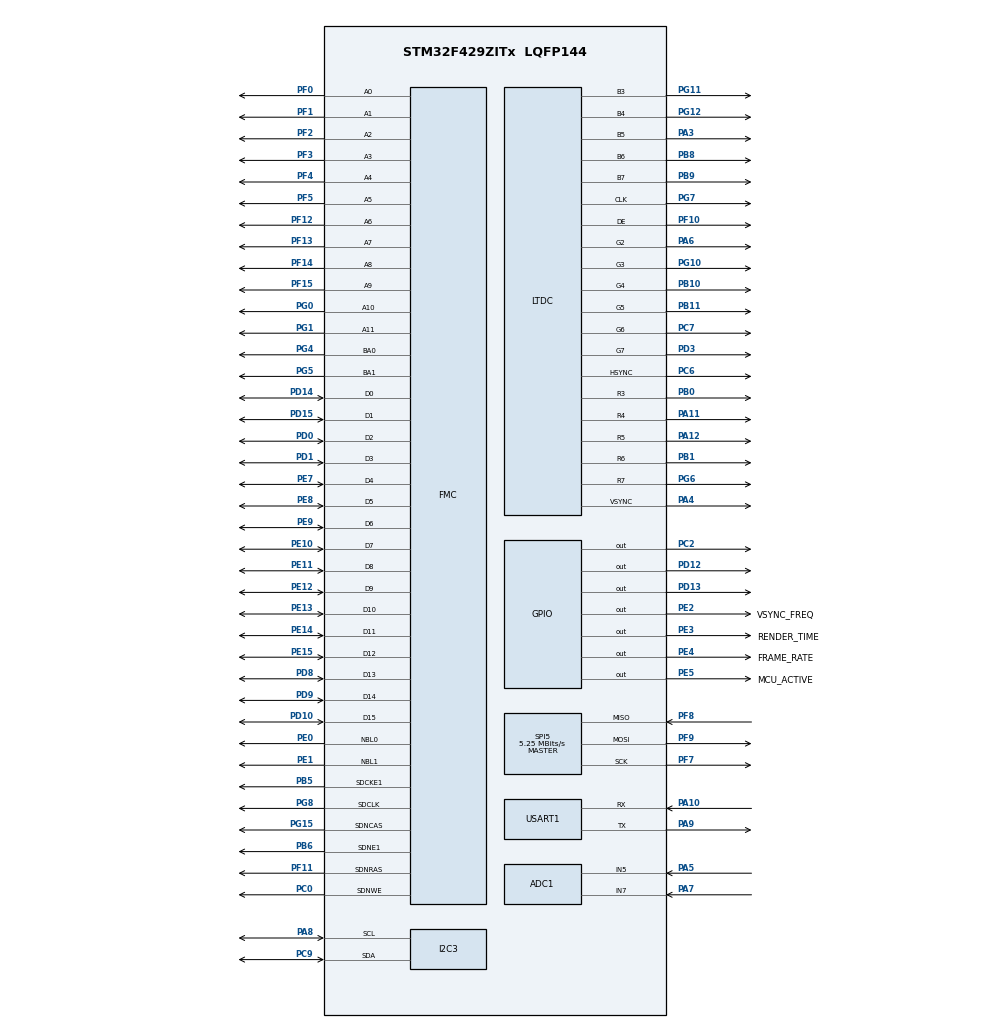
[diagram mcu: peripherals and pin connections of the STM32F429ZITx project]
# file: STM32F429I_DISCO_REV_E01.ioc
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ADC1.Channel-0\#ChannelRegularConversion=ADC_CHANNEL_5
ADC1.Channel-1\#ChannelRegularConversion=ADC_CHANNEL_7
ADC1.NbrOfConversion=2
ADC1.NbrOfConversionFlag=1
ADC1.Rank-0\#ChannelRegularConversion=1
ADC1.Rank-1\#ChannelRegularConversion=2
ADC1.SamplingTime-0\#ChannelRegularConversion=ADC_SAMPLETIME_3CYCLES
ADC1.SamplingTime-1\#ChannelRegularConversion=ADC_SAMPLETIME_3CYCLES
ADC1.master=1
DMA2D.ColorMode=DMA2D_OUTPUT_RGB565
FMC.CASLatency1=FMC_SDRAM_CAS_LATENCY_3
FMC.ExitSelfRefreshDelay1=7
FMC.LoadToActiveDelay1=2
FMC.RCDDelay1=2
FMC.RPDelay1=2
FMC.ReadPipeDelay1=FMC_SDRAM_RPIPE_DELAY_1
FMC.RowCycleDelay1=7
FMC.SDClockPeriod1=FMC_SDRAM_CLOCK_PERIOD_2
FMC.SelfRefreshTime1=4
FMC.WriteRecoveryTime1=3
FREERTOS.Tasks01=defaultTask,24,128,StartDefaultTask,Default,NULL,Dynamic,NULL,NULL;GUI_Task,24,8192,TouchGFX_Task,As external,NULL,Dynamic,NULL,NULL
FREERTOS.configMAX_PRIORITIES=56
FREERTOS.configTOTAL_HEAP_SIZE=65536
FREERTOS.configUSE_APPLICATION_TASK_TAG=1
FREERTOS.configUSE_NEWLIB_REENTRANT=1
I2C3.Analog_Filter=I2C_ANALOGFILTER_DISABLE
LTDC.ActiveH=320
LTDC.ActiveW=240
LTDC.Alpha_L0=255
LTDC.BlendingFactor1_L0=LTDC_BLENDING_FACTOR1_CA
LTDC.BlendingFactor2_L0=LTDC_BLENDING_FACTOR2_CA
LTDC.Blue_L0=0
LTDC.HBP=20
LTDC.HFP=10
LTDC.HSync=10
LTDC.ImageHeight_L0=320
LTDC.ImageWidth_L0=240
LTDC.Layers=0
LTDC.PixelFormat_L0=LTDC_PIXEL_FORMAT_RGB565
LTDC.VFP=4
LTDC.VSync=2
LTDC.WindowX1_L0=240
LTDC.WindowY1_L0=320
Mcu.Family=STM32F4
Mcu.Name=STM32F429ZITx
Mcu.Package=LQFP144
NVIC.ADC_IRQn=true\:5\:0\:false\:false\:true\:true\:true\:true\:true
NVIC.DMA2D_IRQn=true\:5\:0\:true\:false\:true\:false\:true\:true\:true
NVIC.LTDC_IRQn=true\:5\:0\:true\:false\:true\:false\:true\:true\:true
NVIC.PriorityGroup=NVIC_PRIORITYGROUP_4
NVIC.TIM6_DAC_IRQn=true\:0\:0\:false\:false\:true\:false\:false\:true\:true
NVIC.TimeBase=TIM6_DAC_IRQn
NVIC.TimeBaseIP=TIM6
NVIC.USART1_IRQn=true\:5\:0\:false\:false\:true\:true\:true\:true\:true
PA10.Mode=Asynchronous
PA10.Signal=USART1_RX
PA11.GPIO_Speed=GPIO_SPEED_FREQ_HIGH
PA11.Mode=RGB565
PA11.Signal=LTDC_R4
PA12.GPIO_Speed=GPIO_SPEED_FREQ_HIGH
PA12.Mode=RGB565
PA12.Signal=LTDC_R5
PA3.GPIO_Speed=GPIO_SPEED_FREQ_HIGH
PA3.Mode=RGB565
PA3.Signal=LTDC_B5
PA4.GPIO_Speed=GPIO_SPEED_FREQ_HIGH
PA4.Mode=RGB565
PA4.Signal=LTDC_VSYNC
PA5.Signal=ADCx_IN5
PA6.GPIO_Speed=GPIO_SPEED_FREQ_HIGH
PA6.Mode=RGB565
PA6.Signal=LTDC_G2
PA7.Signal=ADCx_IN7
PA8.GPIO_Pu=GPIO_PULLUP
PA8.Mode=I2C
PA8.Signal=I2C3_SCL
PA9.Mode=Asynchronous
PA9.Signal=USART1_TX
PB0.GPIO_Speed=GPIO_SPEED_FREQ_HIGH
PB0.Mode=RGB565
PB0.Signal=LTDC_R3
PB1.GPIO_Speed=GPIO_SPEED_FREQ_HIGH
PB1.Mode=RGB565
PB1.Signal=LTDC_R6
PB10.GPIO_Speed=GPIO_SPEED_FREQ_HIGH
PB10.Mode=RGB565
PB10.Signal=LTDC_G4
PB11.GPIO_Speed=GPIO_SPEED_FREQ_HIGH
PB11.Mode=RGB565
PB11.Signal=LTDC_G5
PB5.Mode=SdramChipSelect2_1
PB5.Signal=FMC_SDCKE1
PB6.Mode=SdramChipSelect2_1
PB6.Signal=FMC_SDNE1
PB8.GPIO_Speed=GPIO_SPEED_FREQ_HIGH
PB8.Mode=RGB565
PB8.Signal=LTDC_B6
PB9.GPIO_Speed=GPIO_SPEED_FREQ_HIGH
PB9.Mode=RGB565
PB9.Signal=LTDC_B7
PC0.Signal=FMC_SDNWE
PC2.GPIO_Speed=GPIO_SPEED_FREQ_HIGH
PC2.Signal=GPIO_Output
PC6.GPIO_Speed=GPIO_SPEED_FREQ_HIGH
PC6.Mode=RGB565
PC6.Signal=LTDC_HSYNC
PC7.GPIO_Speed=GPIO_SPEED_FREQ_HIGH
PC7.Mode=RGB565
PC7.Signal=LTDC_G6
PC9.GPIO_Pu=GPIO_PULLUP
PC9.Mode=I2C
PC9.Signal=I2C3_SDA
PD0.Signal=FMC_D2_DA2
PD1.Signal=FMC_D3_DA3
PD10.Signal=FMC_D15_DA15
PD12.GPIO_Speed=GPIO_SPEED_FREQ_HIGH
PD12.Signal=GPIO_Output
PD13.GPIO_Speed=GPIO_SPEED_FREQ_HIGH
PD13.Signal=GPIO_Output
PD14.Signal=FMC_D0_DA0
PD15.Signal=FMC_D1_DA1
PD3.GPIO_Speed=GPIO_SPEED_FREQ_HIGH
PD3.Mode=RGB565
PD3.Signal=LTDC_G7
PD8.Signal=FMC_D13_DA13
PD9.Signal=FMC_D14_DA14
PE0.Signal=FMC_NBL0
PE1.Signal=FMC_NBL1
PE10.Signal=FMC_D7_DA7
PE11.Signal=FMC_D8_DA8
PE12.Signal=FMC_D9_DA9
PE13.Signal=FMC_D10_DA10
PE14.Signal=FMC_D11_DA11
PE15.Signal=FMC_D12_DA12
PE2.GPIO_Label=VSYNC_FREQ
PE2.GPIO_Speed=GPIO_SPEED_FREQ_VERY_HIGH
PE2.Signal=GPIO_Output
PE3.GPIO_Label=RENDER_TIME
PE3.GPIO_Speed=GPIO_SPEED_FREQ_VERY_HIGH
PE3.Signal=GPIO_Output
PE4.GPIO_Label=FRAME_RATE
PE4.GPIO_Speed=GPIO_SPEED_FREQ_VERY_HIGH
PE4.Signal=GPIO_Output
PE5.GPIO_Label=MCU_ACTIVE
PE5.GPIO_Speed=GPIO_SPEED_FREQ_VERY_HIGH
PE5.Signal=GPIO_Output
PE7.Signal=FMC_D4_DA4
PE8.Signal=FMC_D5_DA5
PE9.Signal=FMC_D6_DA6
PF0.Signal=FMC_A0
PF1.Signal=FMC_A1
PF10.GPIO_Speed=GPIO_SPEED_FREQ_HIGH
PF10.Mode=RGB565
PF10.Signal=LTDC_DE
PF11.Signal=FMC_SDNRAS
PF12.Signal=FMC_A6
PF13.Signal=FMC_A7
PF14.Signal=FMC_A8
PF15.Signal=FMC_A9
PF2.Signal=FMC_A2
PF3.Signal=FMC_A3
PF4.Signal=FMC_A4
PF5.Signal=FMC_A5
PF7.Mode=Full_Duplex_Master
PF7.Signal=SPI5_SCK
PF8.Mode=Full_Duplex_Master
PF8.Signal=SPI5_MISO
PF9.Mode=Full_Duplex_Master
PF9.Signal=SPI5_MOSI
PG0.Signal=FMC_A10
PG1.Signal=FMC_A11
PG10.GPIO_Speed=GPIO_SPEED_FREQ_HIGH
PG10.Mode=RGB565
PG10.Signal=LTDC_G3
PG11.GPIO_Speed=GPIO_SPEED_FREQ_HIGH
PG11.Mode=RGB565
PG11.Signal=LTDC_B3
PG12.GPIO_Speed=GPIO_SPEED_FREQ_HIGH
PG12.Mode=RGB565
PG12.Signal=LTDC_B4
PG15.Signal=FMC_SDNCAS
PG4.Signal=FMC_A14_BA0
PG5.Signal=FMC_A15_BA1
PG6.GPIO_Speed=GPIO_SPEED_FREQ_HIGH
PG6.Mode=RGB565
PG6.Signal=LTDC_R7
PG7.GPIO_Speed=GPIO_SPEED_FREQ_HIGH
PG7.Mode=RGB565
PG7.Signal=LTDC_CLK
PG8.Signal=FMC_SDCLK
PH0/OSC_IN.Mode=HSE-External-Oscillator
PH0/OSC_IN.Signal=RCC_OSC_IN
PH1/OSC_OUT.Mode=HSE-External-Oscillator
PH1/OSC_OUT.Signal=RCC_OSC_OUT
ProjectManager.HeapSize=0xA00
ProjectManager.StackSize=0xA00
ProjectManager.TargetToolchain=STM32CubeIDE
RCC.48MHZClocksFreq_Value=84000000
RCC.AHBFreq_Value=168000000
RCC.APB1CLKDivider=RCC_HCLK_DIV4
RCC.APB1Freq_Value=42000000
RCC.APB1TimFreq_Value=84000000
RCC.APB2CLKDivider=RCC_HCLK_DIV2
RCC.APB2Freq_Value=84000000
RCC.APB2TimFreq_Value=168000000
RCC.CortexFreq_Value=168000000
RCC.HCLKFreq_Value=168000000
RCC.HSE_VALUE=8000000
RCC.HSI_VALUE=16000000
RCC.LSE_VALUE=32768
RCC.PLLM=8
RCC.PLLN=336
RCC.PLLSAIDivR=RCC_PLLSAIDIVR_8
RCC.PLLSAIN=192
RCC.PLLSAIR=4
RCC.PLLSourceVirtual=RCC_PLLSOURCE_HSE
RCC.SYSCLKFreq_VALUE=168000000
RCC.SYSCLKSource=RCC_SYSCLKSOURCE_PLLCLK
RCC.VCOOutputFreq_Value=336000000
SH.ADCx_IN5.0=ADC1_IN5,IN5
SH.ADCx_IN7.0=ADC1_IN7,IN7
SH.FMC_A0.0=FMC_A0,12b-sda1
SH.FMC_A1.0=FMC_A1,12b-sda1
SH.FMC_A10.0=FMC_A10,12b-sda1
SH.FMC_A11.0=FMC_A11,12b-sda1
SH.FMC_A14_BA0.0=FMC_BA0,FourSdramBanks1
SH.FMC_A15_BA1.0=FMC_BA1,FourSdramBanks1
SH.FMC_A2.0=FMC_A2,12b-sda1
SH.FMC_A3.0=FMC_A3,12b-sda1
SH.FMC_A4.0=FMC_A4,12b-sda1
SH.FMC_A5.0=FMC_A5,12b-sda1
SH.FMC_A6.0=FMC_A6,12b-sda1
SH.FMC_A7.0=FMC_A7,12b-sda1
SH.FMC_A8.0=FMC_A8,12b-sda1
SH.FMC_A9.0=FMC_A9,12b-sda1
SH.FMC_D0_DA0.0=FMC_D0,sd-16b-d1
SH.FMC_D10_DA10.0=FMC_D10,sd-16b-d1
SH.FMC_D11_DA11.0=FMC_D11,sd-16b-d1
SH.FMC_D12_DA12.0=FMC_D12,sd-16b-d1
SH.FMC_D13_DA13.0=FMC_D13,sd-16b-d1
SH.FMC_D14_DA14.0=FMC_D14,sd-16b-d1
SH.FMC_D15_DA15.0=FMC_D15,sd-16b-d1
SH.FMC_D1_DA1.0=FMC_D1,sd-16b-d1
SH.FMC_D2_DA2.0=FMC_D2,sd-16b-d1
SH.FMC_D3_DA3.0=FMC_D3,sd-16b-d1
SH.FMC_D4_DA4.0=FMC_D4,sd-16b-d1
SH.FMC_D5_DA5.0=FMC_D5,sd-16b-d1
SH.FMC_D6_DA6.0=FMC_D6,sd-16b-d1
SH.FMC_D7_DA7.0=FMC_D7,sd-16b-d1
SH.FMC_D8_DA8.0=FMC_D8,sd-16b-d1
SH.FMC_D9_DA9.0=FMC_D9,sd-16b-d1
SH.FMC_NBL0.0=FMC_NBL0,Sd2ByteEnable1
SH.FMC_NBL1.0=FMC_NBL1,Sd2ByteEnable1
SH.FMC_SDCLK.0=FMC_SDCLK,12b-sda1
SH.FMC_SDNCAS.0=FMC_SDNCAS,12b-sda1
SH.FMC_SDNRAS.0=FMC_SDNRAS,12b-sda1
SH.FMC_SDNWE.0=FMC_SDNWE,12b-sda1
SPI5.BaudRatePrescaler=SPI_BAUDRATEPRESCALER_16
SPI5.CLKPolarity=SPI_POLARITY_LOW
SPI5.CRCCalculation=SPI_CRCCALCULATION_DISABLE
SPI5.CalculateBaudRate=5.25 MBits/s
SPI5.Direction=SPI_DIRECTION_2LINES
SPI5.Mode=SPI_MODE_MASTER
SPI5.VirtualType=VM_MASTER
STMicroelectronics.X-CUBE-TOUCHGFX.4.23.2.ApplicationCcGraphicsJjApplication=TouchGFXOoGenerator
STMicroelectronics.X-CUBE-TOUCHGFX.4.23.2.tgfx_buffering_strategy=Double
STMicroelectronics.X-CUBE-TOUCHGFX.4.23.2.tgfx_display_interface=disp_ltdc
STMicroelectronics.X-CUBE-TOUCHGFX.4.23.2.tgfx_hardware_accelerator=dma_2d
STMicroelectronics.X-CUBE-TOUCHGFX.4.23.2.tgfx_vector_fonts=Enabled
STMicroelectronics.X-CUBE-TOUCHGFX.4.23.2.tgfx_vector_rendering=Software
STMicroelectronics.X-CUBE-TOUCHGFX.4.23.2.tgfx_vsync=vsync_ltdc
USART1.VirtualMode=VM_ASYNC
VP_CRC_VS_CRC.Mode=CRC_Activate
VP_DMA2D_VS_DMA2D.Mode=DMA2D_Activate
VP_FREERTOS_VS_CMSIS_V2.Mode=CMSIS_V2
VP_STMicroelectronics.X-CUBE-TOUCHGFX_VS_GraphicsJjApplication_4.23.2.Mode=GraphicsJjApplication
VP_SYS_VS_tim6.Mode=TIM6
board=custom

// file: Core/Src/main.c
/* USER CODE BEGIN Header */
/**
 ******************************************************************************
 * @file           : main.c
 * @brief          : Main program body
 ******************************************************************************
 * @attention
 *
 * <h2><center>&copy; Copyright (c) 2020 STMicroelectronics.
 * All rights reserved.</center></h2>
 *
 * This software component is licensed by ST under Ultimate Liberty license
 * SLA0044, the "License"; You may not use this file except in compliance with
 * the License. You may obtain a copy of the License at:
 *                             www.st.com/SLA0044
 *
 ******************************************************************************
 */
//#define DISPLAY_MENU_COMMAND 0
/* USER CODE END Header */
#include "main.h"
#include "gpio.h"
#include "crc.h"
#include "i2c.h"
#include "spi.h"
#include "ltdc.h"
#include "dma.h"
#include "adc.h"
#include "uart.h"
#include "fmc.h"
#include "clock.h"
#include "cmsis_os.h"
#include "app_touchgfx.h"
#include "semphr.h"

/* USER CODE BEGIN Includes */
#include "Components/ili9341/ili9341.h"
#include "temp_sens.h"
#include "data_UI_def.h"
#include "date_time_def.h"
#include "cli.h"
#include "utilities.h"

/* USER CODE END Includes */

/* USER CODE BEGIN PV */
TaskHandle_t GUI_TaskHandle;
TaskHandle_t GetSensData_TaskHandle;
TaskHandle_t CLI_TaskHandle;

BaseType_t GUI_TaskFlag;
BaseType_t GetSensData_TaskFlag;
BaseType_t CLI_TaskFlag;

xQueueHandle dataQueue;
xQueueHandle cliQueue;

xSemaphoreHandle i2c_semaphore;

/* USER CODE END PV */

void CLI_Task(void *argument);
void GetSensDataTask(void *argument);
extern void TouchGFX_Task(void *argument);
void setBrightness(uint8_t);

/* Link function for LCD peripheral */
void LCD_IO_Init(void);
void LCD_IO_WriteData(uint16_t RegValue);
void LCD_IO_WriteReg(uint8_t Reg);
uint32_t LCD_IO_ReadData(uint16_t RegValue, uint8_t ReadSize);
void LCD_Delay(uint32_t delay);

/* IOExpander IO functions */
void IOE_Init(void);
void IOE_ITConfig(void);
void IOE_Delay(uint32_t Delay);
void IOE_Write(uint8_t Addr, uint8_t Reg, uint8_t Value);
uint8_t IOE_Read(uint8_t Addr, uint8_t Reg);
uint16_t IOE_ReadMultiple(uint8_t Addr, uint8_t Reg, uint8_t *pBuffer,
		uint16_t Length);

/* USER CODE END PFP */

int main(void) {

	/* USER CODE BEGIN 1 */
	i2c_semaphore = xSemaphoreCreateBinary();
	xSemaphoreGive(i2c_semaphore); //After creation to be free

	/* USER CODE END 1 */

	/* MCU Configuration--------------------------------------------------------*/

	/* Reset of all peripherals, Initializes the Flash interface and the Systick. */
	HAL_Init();

	/* Configure the system clock */
	SystemClock_Config();

	/* Initialize all configured peripherals */
	MX_GPIO_Init();
	MX_CRC_Init();
	MX_I2C3_Init();
	MX_SPI5_Init();
	MX_FMC_Init();
	MX_LTDC_Init();
	MX_DMA2D_Init();
	MX_ADC1_Init();
	MX_USART1_UART_Init();
	MX_TouchGFX_Init();
	/* Call PreOsInit function */
	MX_TouchGFX_PreOSInit();
	/* USER CODE BEGIN 2 */

	/* Init BME680*/

	/*Task creation*/
	GUI_TaskFlag = xTaskCreate(TouchGFX_Task, "TouchGFX_Task", 8192, NULL, osPriorityNormal,
			&GUI_TaskHandle);

	GetSensData_TaskFlag = xTaskCreate(GetSensDataTask, "GetSensDataTask", 128, NULL, osPriorityNormal,
			&GetSensData_TaskHandle);

	CLI_TaskFlag = xTaskCreate(CLI_Task, "Command Line Interface", 128, NULL, osPriorityNormal,
			&CLI_TaskHandle);

	dataQueue = xQueueCreate(1, sizeof(SensData_t));
	cliQueue = xQueueCreate(1, sizeof(SensData_t));

	/*Check if task and semaphore creation is successful*/
	if(GUI_TaskFlag != pdPASS){
		vTaskDelete(GUI_TaskHandle);
	}
	if(GetSensData_TaskFlag != pdPASS){
		vTaskDelete(GetSensData_TaskHandle);
	}
	if(CLI_TaskFlag != pdPASS){
		vTaskDelete(CLI_TaskHandle);
	}
	if(i2c_semaphore == NULL){

		/* Indicates semaphore creation failed*/
		HAL_GPIO_WritePin(GPIOG, GPIO_PIN_14, GPIO_PIN_SET);
	}
	if(dataQueue == NULL){
		HAL_GPIO_WritePin(GPIOG, GPIO_PIN_14, GPIO_PIN_SET);
	}
	if(cliQueue == NULL){
			HAL_GPIO_WritePin(GPIOG, GPIO_PIN_14, GPIO_PIN_SET);
	}

	vQueueAddToRegistry(dataQueue, "DataQueue");
	vQueueAddToRegistry(dataQueue, "CLIQueue");

	/*Start freeRTOS scheduler*/
	vTaskStartScheduler();
	/* USER CODE END 2 */

	while (1) {

	}
}

/**
 * @brief  IOE Low Level Initialization.
 */
void IOE_Init(void) {
	//Dummy function called when initializing to stmpe811 to setup the i2c.
	//This is done with cubmx and is therfore not done here.
}

/**
 * @brief  IOE Low Level Interrupt configuration.
 */
void IOE_ITConfig(void) {
	//Dummy function called when initializing to stmpe811 to setup interupt for the i2c.
	//The interupt is not used in our case, therefore nothing is done here.
}

/**
 * @brief  IOE Writes single data operation.
 * @param  Addr: I2C Address
 * @param  Reg: Reg Address
 * @param  Value: Data to be written
 */
void IOE_Write(uint8_t Addr, uint8_t Reg, uint8_t Value) {
	I2C3_WriteData(Addr, Reg, Value);
}

/**
 * @brief  IOE Reads single data.
 * @param  Addr: I2C Address
 * @param  Reg: Reg Address
 * @retval The read data
 */
uint8_t IOE_Read(uint8_t Addr, uint8_t Reg) {
	return I2C3_ReadData(Addr, Reg);
}

/**
 * @brief  IOE Reads multiple data.
 * @param  Addr: I2C Address
 * @param  Reg: Reg Address
 * @param  pBuffer: pointer to data buffer
 * @param  Length: length of the data
 * @retval 0 if no problems to read multiple data
 */
uint16_t IOE_ReadMultiple(uint8_t Addr, uint8_t Reg, uint8_t *pBuffer,
		uint16_t Length) {
	return I2C3_ReadBuffer(Addr, Reg, pBuffer, Length);
}

/**
 * @brief  IOE Delay.
 * @param  Delay in ms
 */
void IOE_Delay(uint32_t Delay) {
	HAL_Delay(Delay);
}

void LCD_IO_Init(void) {
	/* Set or Reset the control line */
	HAL_GPIO_WritePin(GPIOC, GPIO_PIN_2, GPIO_PIN_RESET);
	HAL_GPIO_WritePin(GPIOC, GPIO_PIN_2, GPIO_PIN_SET);
}

/**
 * @brief  Writes register value.
 */
void LCD_IO_WriteData(uint16_t RegValue) {
	/* Set WRX to send data */
	HAL_GPIO_WritePin(GPIOD, GPIO_PIN_13, GPIO_PIN_SET);

	/* Reset LCD control line(/CS) and Send data */
	HAL_GPIO_WritePin(GPIOC, GPIO_PIN_2, GPIO_PIN_RESET);
	SPI5_Write(RegValue);

	/* Deselect: Chip Select high */
	HAL_GPIO_WritePin(GPIOC, GPIO_PIN_2, GPIO_PIN_SET);
}

/**
 * @brief  Writes register address.
 */
void LCD_IO_WriteReg(uint8_t Reg) {
	/* Reset WRX to send command */
	HAL_GPIO_WritePin(GPIOD, GPIO_PIN_13, GPIO_PIN_RESET);

	/* Reset LCD control line(/CS) and Send command */
	HAL_GPIO_WritePin(GPIOC, GPIO_PIN_2, GPIO_PIN_RESET);
	SPI5_Write(Reg);

	/* Deselect: Chip Select high */
	HAL_GPIO_WritePin(GPIOC, GPIO_PIN_2, GPIO_PIN_SET);
}

/**
 * @brief  Reads register value.
 * @param  RegValue Address of the register to read
 * @param  ReadSize Number of bytes to read
 * @retval Content of the register value
 */
uint32_t LCD_IO_ReadData(uint16_t RegValue, uint8_t ReadSize) {
	uint32_t readvalue = 0;

	/* Select: Chip Select low */
	HAL_GPIO_WritePin(GPIOC, GPIO_PIN_2, GPIO_PIN_RESET);

	/* Reset WRX to send command */
	HAL_GPIO_WritePin(GPIOD, GPIO_PIN_13, GPIO_PIN_RESET);

	SPI5_Write(RegValue);

	readvalue = SPI5_Read(ReadSize);

	/* Set WRX to send data */
	HAL_GPIO_WritePin(GPIOD, GPIO_PIN_13, GPIO_PIN_SET);

	/* Deselect: Chip Select high */
	HAL_GPIO_WritePin(GPIOC, GPIO_PIN_2, GPIO_PIN_SET);

	return readvalue;
}

/**
 * @brief  Wait for loop in ms.
 * @param  Delay in ms.
 */
void LCD_Delay(uint32_t Delay) {
	HAL_Delay(Delay);
}

void GetSensDataTask(void *argument) {

	SensData_t data_UI;
	SensorInit(&sensor_In, &meas_period_In, SENS_IN_NUM);
	SensorInit(&sensor_Out, &meas_period_Out, SENS_OUT_NUM);

	for (;;) {

		ADC_Select_CH5(&data_UI); //get ADC value from PA5 <Ambient light>

		ADC_Select_CH7(&data_UI); //get ADC value from PA7 <Gas sensor>

		GetBMEdata(&data_UI);

		if(uxQueueSpacesAvailable(dataQueue) == 1){

			xQueueSend(dataQueue, &data_UI,0);
		}

		if(uxQueueSpacesAvailable(cliQueue) == 1){

			xQueueSend(cliQueue, &data_UI,0);
		}

		osDelay(500);
	}
}

void CLI_Task(void *argument) {

	SensData_t data_UI;

	HAL_UART_Receive_IT(&huart1, (uint8_t*) &msg[msgIDX], 1);
	for (;;) {

		if(uxQueueSpacesAvailable(cliQueue) == 0){

			xQueueReceive(cliQueue, &data_UI, 0);
		}

		xTaskNotifyWait(0, 1, NULL, portMAX_DELAY);

		CLIHandler(&data_UI, &huart1, msg, &msgIDX);

	}
}

void HAL_UART_RxCpltCallback(UART_HandleTypeDef *huart) {
	xTaskNotifyFromISR(CLI_TaskHandle, 0, eNoAction, NULL);
	HAL_UART_Transmit(&huart1, (uint8_t*)&msg[msgIDX], 1, 100);
}
/* USER CODE END 4 */

void HAL_TIM_PeriodElapsedCallback(TIM_HandleTypeDef *htim) {
	if (htim->Instance == TIM6) {
		HAL_IncTick();
	}
}

void Error_Handler(void) {
}
